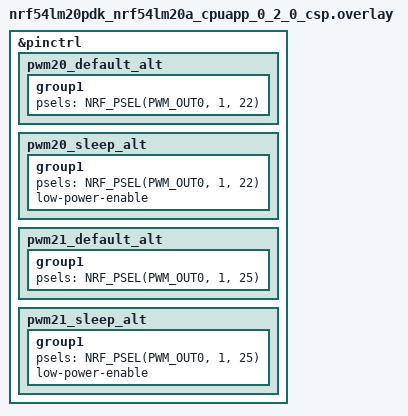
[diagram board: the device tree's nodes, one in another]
/*
 * Copyright (c) 2025 Nordic Semiconductor ASA
 *
 * SPDX-License-Identifier: LicenseRef-Nordic-5-Clause
 */

&pinctrl {
	pwm20_default_alt: pwm20_default_alt {
		group1 {
			psels = <NRF_PSEL(PWM_OUT0, 1, 22)>;
		};
	};

	pwm20_sleep_alt: pwm20_sleep_alt {
		group1 {
			psels = <NRF_PSEL(PWM_OUT0, 1, 22)>;
			low-power-enable;
		};
	};

	pwm21_default_alt: pwm21_default_alt {
		group1 {
			psels = <NRF_PSEL(PWM_OUT0, 1, 25)>;
		};
	};

	pwm21_sleep_alt: pwm21_sleep_alt {
		group1 {
			psels = <NRF_PSEL(PWM_OUT0, 1, 25)>;
			low-power-enable;
		};
	};
};
